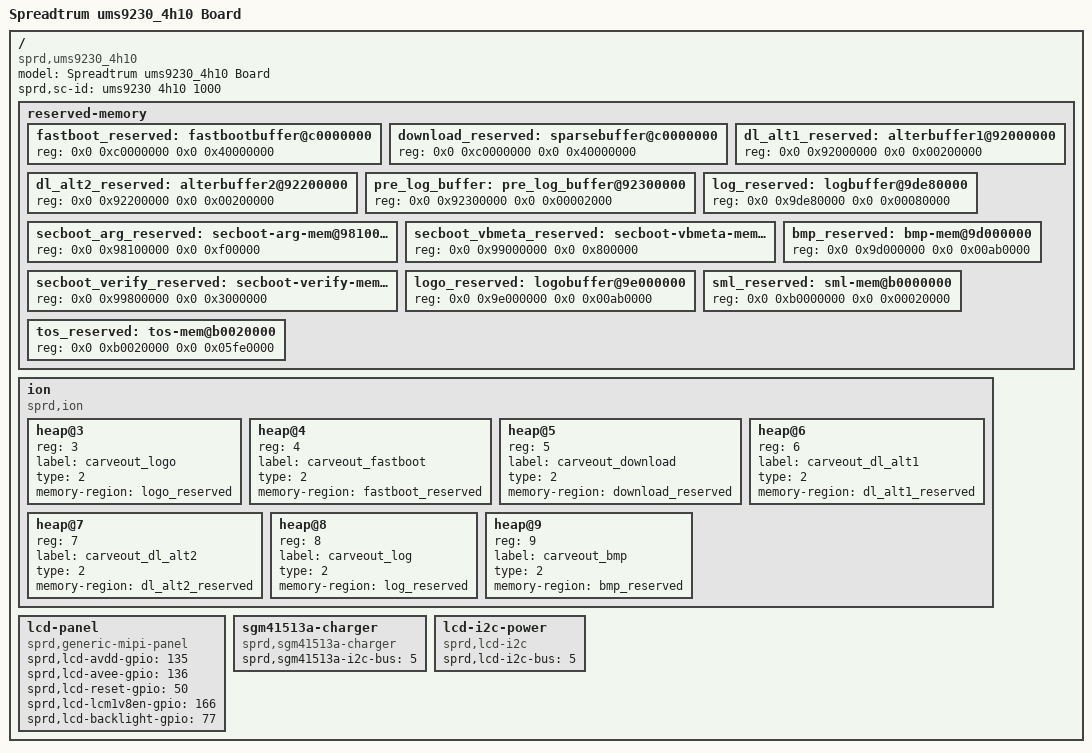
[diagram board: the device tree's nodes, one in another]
/*
 * Spreadtrum ums9230_4h10 board DTS file
 *
 * Copyright (C) 2016, Spreadtrum Communications Inc.
 *
 * This file is licensed under a dual GPLv2 or X11 license.
 */

/dts-v1/;

#include "ums9230.dtsi"
//#include "lcd/lcd_g40396_truly_mipi_fhd.dtsi"
//#include "lcd/lcd_dummy_mipi.dtsi"
#include "lcd/lcd_BL_TA4RUS07VOFMZTB_mipi_fhd.dtsi"

/ {
	model = "Spreadtrum ums9230_4h10 Board";

	compatible = "sprd,ums9230_4h10";

	sprd,sc-id = "ums9230 4h10 1000";

	reserved-memory {
		#address-cells = <2>;
		#size-cells = <2>;
		ranges;

		fastboot_reserved: fastbootbuffer@c0000000{
			reg = <0x0 0xc0000000 0x0 0x40000000>;
		};

		download_reserved: sparsebuffer@c0000000{
			reg = <0x0 0xc0000000 0x0 0x40000000>;
		};

		dl_alt1_reserved: alterbuffer1@92000000{
			reg = <0x0 0x92000000 0x0 0x00200000>;
		};

		dl_alt2_reserved: alterbuffer2@92200000{
			reg = <0x0 0x92200000 0x0 0x00200000>;
		};

		pre_log_buffer: pre_log_buffer@92300000{
			reg = <0x0 0x92300000 0x0 0x00002000>;
		};

		log_reserved: logbuffer@9de80000{
			reg = <0x0 0x9de80000 0x0 0x00080000>;
		};

		secboot_arg_reserved: secboot-arg-mem@98100000{
			reg = <0x0 0x98100000 0x0 0xf00000>;
		};

		secboot_vbmeta_reserved: secboot-vbmeta-mem@99000000{
			reg = <0x0 0x99000000 0x0 0x800000>;
		};

		secboot_verify_reserved: secboot-verify-mem@99800000{
			reg = <0x0 0x99800000 0x0 0x3000000>;
		};

		bmp_reserved: bmp-mem@9d000000 {
			reg = <0x0 0x9d000000 0x0 0x00ab0000>;
		};

		/* 1088 * 2560 * 4 Bytes and 4K aligned */
		logo_reserved: logobuffer@9e000000 {
			reg = <0x0 0x9e000000 0x0 0x00ab0000>;
		};

		/* must be 4K aligned */
		sml_reserved: sml-mem@b0000000{
			reg = <0x0 0xb0000000 0x0 0x00020000>;
		};

		tos_reserved: tos-mem@b0020000{
			reg = <0x0 0xb0020000 0x0 0x05fe0000>;
		};
	};

	ion {
		compatible = "sprd,ion";
		#address-cells = <1>;
		#size-cells = <0>;

		heap@3 {
			reg = <3>;
			label = "carveout_logo";
			type = <2>;
			memory-region = <&logo_reserved>;
		};

		heap@4 {
			reg = <4>;
			label = "carveout_fastboot";
			type = <2>;
			memory-region = <&fastboot_reserved>;
		};

		heap@5 {
			reg = <5>;
			label = "carveout_download";
			type = <2>;
			memory-region = <&download_reserved>;
		};

		heap@6 {
			reg = <6>;
			label = "carveout_dl_alt1";
			type = <2>;
			memory-region = <&dl_alt1_reserved>;
		};

		heap@7 {
			reg = <7>;
			label = "carveout_dl_alt2";
			type = <2>;
			memory-region = <&dl_alt2_reserved>;
		};

		heap@8 {
			reg = <8>;
			label = "carveout_log";
			type = <2>;
			memory-region = <&log_reserved>;
		};

		heap@9 {
			reg = <9>;
			label = "carveout_bmp";
			type = <2>;
			memory-region = <&bmp_reserved>;
		};
	};

	lcd-panel {
		compatible = "sprd,generic-mipi-panel";
		sprd,lcd-avdd-gpio = <135>;
		sprd,lcd-avee-gpio = <136>;
		sprd,lcd-reset-gpio = <50>;
		sprd,lcd-lcm1v8en-gpio = <166>;
		sprd,lcd-backlight-gpio = <77>;
	};

	sgm41513a-charger {
		compatible = "sprd,sgm41513a-charger";
		sprd,sgm41513a-i2c-bus = <5>;
	};

	lcd-i2c-power {
		compatible = "sprd,lcd-i2c";
		sprd,lcd-i2c-bus = <5>;
	};

};
